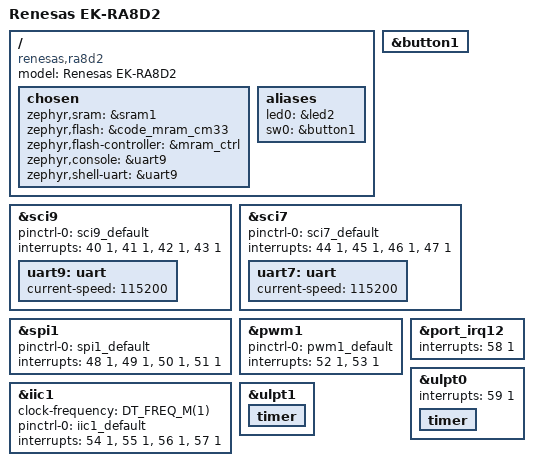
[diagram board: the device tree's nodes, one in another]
/*
 * Copyright (c) 2026 Renesas Electronics Corporation
 * SPDX-License-Identifier: Apache-2.0
 */

/dts-v1/;

#include <renesas/ra/ra8/r7ka8d2kflcac_cm33.dtsi>
#include "ek_ra8d2.dtsi"

/ {
	model = "Renesas EK-RA8D2";
	compatible = "renesas,ra8d2", "renesas,ra8";

	chosen {
		zephyr,sram = &sram1;
		zephyr,flash = &code_mram_cm33;
		zephyr,flash-controller = &mram_ctrl;
		zephyr,console = &uart9;
		zephyr,shell-uart = &uart9;
	};

	aliases {
		led0 = &led2;
		sw0 = &button1;
	};
};

&button1 {
	status = "okay";
};

&sci9 {
	pinctrl-0 = <&sci9_default>;
	pinctrl-names = "default";
	interrupts = <40 1>, <41 1>, <42 1>, <43 1>;
	interrupt-names = "rxi", "txi", "tei", "eri";
	status = "okay";

	uart9: uart {
		current-speed = <115200>;
		status = "okay";
	};
};

&sci7 {
	pinctrl-0 = <&sci7_default>;
	pinctrl-names = "default";
	interrupts = <44 1>, <45 1>, <46 1>, <47 1>;
	interrupt-names = "rxi", "txi", "tei", "eri";
	status = "okay";

	uart7: uart {
		current-speed = <115200>;
	};
};

&spi1 {
	pinctrl-0 = <&spi1_default>;
	pinctrl-names = "default";
	interrupts = <48 1>, <49 1>, <50 1>, <51 1>;
	interrupt-names = "rxi", "txi", "tei", "eri";
};

&pwm1 {
	pinctrl-0 = <&pwm1_default>;
	interrupts = <52 1>, <53 1>;
	interrupt-names = "gtioca", "overflow";
	pinctrl-names = "default";
	status = "okay";
};

&iic1 {
	#address-cells = <1>;
	#size-cells = <0>;
	clock-frequency = <DT_FREQ_M(1)>;
	pinctrl-0 = <&iic1_default>;
	pinctrl-names = "default";
	interrupts = <54 1>, <55 1>, <56 1>, <57 1>;
	interrupt-names = "rxi", "txi", "tei", "eri";
};

&port_irq12 {
	interrupts = <58 1>;
	status = "okay";
};

&ulpt0 {
	interrupts = <59 1>;
	interrupt-names = "ulpti";
	status = "okay";

	timer {
		status = "okay";
	};
};

&ulpt1 {
	status = "okay";

	timer {
		status = "okay";
	};
};
